# MMCHS1 register map
Vendor: Texas Instruments
Registers are 32-bit, access per field, reset 0x0 unless marked. A register's access mark holds for its fields unless they carry their own. Offsets are as the file gives them; [hi:lo] are bit positions.

## MMCHS1 (part 2 of 2)
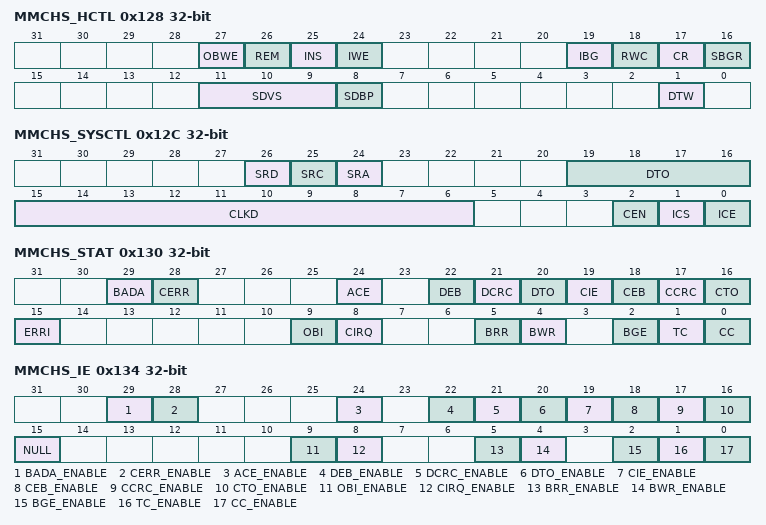
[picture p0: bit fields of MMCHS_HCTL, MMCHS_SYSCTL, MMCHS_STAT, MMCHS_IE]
0x128 MMCHS_HCTL — Control register. This register defines the host controls to set power, wake up and transfer parameters. MMCi.[31:24] = Wake-up control MMCi.[23:16] = Block gap control MMCi.[15:8] = Power control MMCi.[7:0] = Host control
  [27] OBWE rw — Wake-up event enable for 'Out-of-Band' Interrupt.This bit enables wake-up events for 'Out-of-Band' assertion. Wakeup is generated if the wake-up feature is enabled (MMCi.MMCHS_SYSCONFIG[2] ENAWAKEUP bit). The write to this register is ignored when MMCi.MMCHS_CON[14] OBIE bit is not set.
    0=Disable wakeup on 'Out-of-Band' Interrupt; 1=Enable wakeup on 'Out-of-Band' Interrupt
  [26] REM rw — Wake-up event enable on SD card removal.This bit enables wake-up events for card removal assertion. Wakeup is generated if the wake-up feature is enabled (MMCi.MMCHS_SYSCONFIG[2] ENAWAKEUP bit).
    0=Disable wakeup on card removal; 1=Enable wakeup on card removal
  [25] INS rw — Wake-up event enable on SD card insertionThis bit enables wake-up events for card insertion assertion. Wakeup is generated if the wake-up feature is enabled (MMCi.MMCHS_SYSCONFIG[2] ENAWAKEUP bit).
    0=Disable wakeup on card insertion; 1=Enable wakeup on card insertion
  [24] IWE rw — Wake-up event enable on SD card interrupt.This bit enables wake-up events for card interrupt assertion. Wakeup is generated if the wake-up feature is enabled (MMCi.MMCHS_SYSCONFIG[2] ENAWAKEUP bit) and enable status bit is set (MMCi.MMCHS_IE[8] CIRQ_ENABLE bit).
    0=Disable wakeup on card interrupt; 1=Enable wakeup on card interrupt
  [19] IBG rw — Interrupt block at gap.This bit is valid only in 4-bit mode of SDIO card to enable interrupt detection in the interrupt cycle at block gap for a multiple block transfer. For MMC cards and for SD card this bit should be set to 0.
    0=Disable interrupt detection at the block gap in 4-bit mode; 1=Enable interrupt detection at the block gap in 4-bit mode
  [18] RWC rw — Read wait control.The read wait function is optional only for SDIO cards. If the card supports read wait, this bit must be enabled, then requesting a stop at block gap (MMCi.MMCHS_HCTL[16] SBGR bit) generates a read wait period after the current end of block. Be careful, if read wait is not supported it may cause a conflict on mmci_dat line.
    0=Disable Read Wait Control. Suspend/Resume cannot be supported.; 1=Enable Read Wait Control
  [17] CR rw — Continue request.This bit is used to restart a transaction that was stopped by requesting a stop at block gap (MMCi.MMCHS_HCTL[16] SBGR bit). Set this bit to 1 restarts the transfer. The bit is automatically set to 0 by the host controller when transfer has restarted i.e. mmci_dat line is active (MMCi.MMCHS_PSTATE[2] DLA bit) or transferring data (MMCi.MMCHS_PSTATE[8] WTA bit).The Stop at block gap request must be disabled (MMCi.MMCHS_HCTL[16] SBGR bit =0) before setting this bit.
    0=No affect; 1=transfer restart
  [16] SBGR rw — Stop at block gap request. This bit is used to stop executing a transaction at the next block gap. The transfer can restart with a continue request (MMCi.MMCHS_HCTL[17] CR bit) or during a suspend/resume sequence. In case of read transfer, the card must support read wait control. In case of write transfer, the host driver shall set this bit after all block data written. Until the transfer completion (MMCi.MMCHS_STAT[1] TC bit set to 1), the host driver shall leave this bit set to 1.If this bit is set, the local host shall not write to the data register (MMCi.MMCHS_DATA).
    0=Transfer mode; 1=Stop at block gap
  [11:9] SDVS rw — SD bus voltage select (All cards).The host driver should set these bits to select the voltage level for the card according to the voltage supported by the system (MMCi.MMCHS_CAPA[26] VS18 bit, MMCi.MMCHS_CAPA[25] VS30 bit, MMCi.MMCHS_CAPA[24] VS33 bit) before starting a transfer.MMCHS2: This field must be set to 0x5. . MMCHS3: This field must be set to 0x5. .
    5=1.8V (Typical); 6=3.0V (Typical); 7=3.3V (Typical)
  [8] SDBP rw — SD bus power.Before setting this bit, the host driver shall select the SD bus voltage (MMCi.MMCHS_HCTL[11:9] SDVS bits). If the host controller detects the No card state, this bit is automatically set to 0. If the module is power off, a write in the command register (MMCi.MMCHS_CMD) will not start the transfer. A write to this bit has no effect if the selected SD bus voltage is not supported according to capability register (MMCi.MMCHS_CAPA[VS*]).
    0=Power off; 1=Power on
  [1] DTW rw — Data transfer width.For MMC card, this bit must be set following a valid SWITCH command (CMD6) with the correct value and extend CSD index written in the argument. Prior to this command, the MMC card configuration register (CSD and EXT_CSD) must be verified for compliance with This register has no effect when the MMC 8-bit mode is selected (MMCi.MMCHS_CON[5] DW8 bit set to 1)For SD/SDIO cards, this bit must be set following a valid SET_BUS_WIDTH command (ACMD6) with the value written in bit 1 of the argument. Prior to this command, the SD card configuration register (SCR) must be verified for the supported bus width by the SD card.
    0=1-bit Data width (mmci_dat[0] used); 1=4-bit Data width (mmci_dat[3:0] used)
0x12C MMCHS_SYSCTL — SD system control register. This register defines the system controls to set software resets, clock frequency management and data timeout. [31:24] = Software resets [23:16] = Timeout control [15:0] = Clock control
  [26] SRD rw — Software reset for mmci_dat line. This bit is set to 1 for reset and released to 0 when completed .mmci_dat finite state machine in both clock domain are also reset. Here below are the registers cleared by the MMCHS_SYSCTL[26] SRD bit: MMCi.MMCHS_DATA MMCi.MMCHS_PSTATE: BRE, BWE, RTA, WTA, DLA and DATI MMCi.MMCHS_HCTL: SBGR and CR MMCi.MMCHS_STAT: BRR, BWR, BGE and TC Interconnect and MMC buffer data management is reinitialized.
    0=Reset completed; 1=Software reset for mmci_dat line
  [25] SRC rw — Software reset for mmci_cmd line. This bit is set to 1 for reset and released to 0 when completed. mmci_cmd finite state machine in both clock domain are also reset. Here below the registers cleared by the MMCi.MMCHS_SYSCTL[25] SRC bit: MMCi.MMCHS_PSTATE: CMDI MMCi.MMCHS_STAT: CC Interconnect and MMC command status management is reinitialized.
    0=Reset completed; 1=Software reset for mmci_cmd line
  [24] SRA rw — Software reset for all. This bit is set to 1 for reset , and released to 0 when completed. This reset affects the entire host controller except for the card detection circuit and capabilities registers.
    0=Reset completed; 1=Software reset for all the design
  [19:16] DTO rw — Data timeout counter value and busy timeout. This value determines the interval by which mmci_dat lines timeouts are detected.The host driver needs to set this bit field based on - the maximum read access time (NAC) (Refer to the SD Specification Part1 Physical Layer), - the data read access time values (TAAC and NSAC) in the card specific data register (CSD) of the card, - the timeout clock base frequency (MMCi.MMCHS_CAPA[5:0] TCF bits). If the card does not respond within the specified number of cycles, a data timeout error occurs (MMCi.MMCHS_STAT[20] DTO bit). The MMCi.MMCHS_SYSCTL[19,16] DTO bit field is also used to check busy duration, to generate busy timeout for commands with busy response or for busy programming during a write command. Timeout on CRC status is generated if no CRC token is present after a block write.
    0=TCF x 2^13; 1=TCF x 2^14; 14=TCF x 2^27
  [15:6] CLKD rw — Clock frequency select These bits define the ratio between a reference clock frequency (system dependant) and the output clock frequency on the mmci_clk pin of either the memory card (MMC, SD or SDIO).
    0=Clock Ref bypass; 1=Clock Ref bypass; 2=Clock Ref / 2; 3=Clock Ref / 3; 0x3FF=Clock Ref / 1023
  [2] CEN rw — Clock enable. This bit controls if the clock is provided to the card or not.
    0=The clock is not provided to the card . Clock frequency can be changed .; 1=The clock is provided to the card and can be automatically gated when MMCi.[0] AUTOIDLE bit is set to 1 (default value) .The host driver shall wait to set this bit to 1 until the Internal clock is stable (MMCi.[1] ICS bit)
  [1] ICS ro — Internal clock stable (status)This bit indicates either the internal clock is stable or not.
    0=ICS_0_r (The internal clock is not stable.); 1=ICS_1_r (The internal clock is stable after enabling the clock (MMCi.[0] ICE bit) or after changing the clock ratio (MMCi.[15:6] CLKD bits).)
  [0] ICE rw — Internal clock enable. This register controls the internal clock activity.In very low power state, the internal clock is stopped. Note: The activity of the debounce clock (used for wake-up events) and the interface clock (used for reads and writes to the module register map) are not affected by this register.
    0=The internal clock is stopped (very low power state); 1=The internal clock oscillates and can be automatically gated when MMCi.[0] AUTOIDLE bit is set to 1 (default value) 
0x130 MMCHS_STAT — Interrupt status register The interrupt status regroups all the status of the module internal events that can generate an interrupt. [31:16] = Error Interrupt Status [15:0] = Normal Interrupt Status
  [29] BADA rw — Bad access to data space.This bit is set automatically to indicate a bad access to buffer when not allowed:- During a read access to the data register (MMCi.MMCHS_DATA) while buffer reads are not allowed (MMCi.MMCHS_PSTATE[11] BRE bit =0)- During a write access to the data register (MMCi.MMCHS_DATA) while buffer writes are not allowed (MMCi.MMCHS_PSTATE[10] BWE bit=0)
    0=BADA_0_r (No Interrupt.); 0=BADA_0_w (Status bit unchanged); 1=BADA_1_r (Bad Access); 1=BADA_1_w (Status is cleared)
  [28] CERR rw — Card error.This bit is set automatically when there is at least one error in a response of type R1, R1b, R6, R5 or R5b. Only bits referenced as type E (error) in status field in the response can set a card status error. An error bit in the response is flagged only if corresponding bit in card status response error MMCi.MMCHS_CSRE in set.There is no card error detection for autoCMD12 command. The host driver shall read MMCi.MMCHS_RSP76 register to detect error bits in the command response.
    0=CERR_0_r (No Error); 0=CERR_0_w (Status bit unchanged); 1=CERR_1_r (Card error); 1=CERR_1_w (Status is cleared)
  [24] ACE rw — Auto CMD12 error.This bit is set automatically when one of the bits in Auto CMD12 Error status register has changed from 0 to 1.
    0=ACE_0_r (No Error); 0=ACE_0_w (Status bit unchanged); 1=ACE_1_r (AutoCMD12 error); 1=ACE_1_w (Status is cleared)
  [22] DEB rw — Data End Bit error.This bit is set automatically when detecting a 0 at the end bit position of read data on mmci_dat line or at the end position of the CRC status in write mode.
    0=DEB_0_r (No Error); 0=DEB_0_w (Status bit unchanged); 1=DEB_1_r (Data end bit error); 1=DEB_1_w (Status is cleared)
  [21] DCRC rw — Data CRC Error.This bit is set automatically when there is a CRC16 error in the data phase response following a block read command or if there is a 3-bit CRC status different of a position '010' token during a block write command.
    0=DCRC_0_r (No Error.); 0=DCRC_0_w (Status bit unchanged); 1=DCRC_1_r (Data CRC error); 1=DCRC_1_w (Status is cleared)
  [20] DTO rw — Data timeout error. This bit is set automatically according to the following conditions:- Busy timeout for R1b, R5b response type. - Busy timeout after write CRC status.- Write CRC status timeout.- Read data timeout.
    0=DTO_0_r (No error); 0=DTO_0_w (Status bit unchanged); 1=DTO_1_r (Time out); 1=DTO_1_w (Status is cleared)
  [19] CIE rw — Command index error.This bit is set automatically when response index differs from corresponding command index previously emitted. It depends on the enable bit (MMCi.MMCHS_CMD[20] CICE).
    0=CIE_0_r (No error); 0=CIE_0_w (Status bit unchanged); 1=CIE_1_r (Command index error); 1=CIE_1_w (Status is cleared)
  [18] CEB rw — Command end bit error.This bit is set automatically when detecting a 0 at the end bit position of a command response.
    0=CEB_0_r (No error); 0=CEB_0_w (Status bit unchanged); 1=CEB_1_r (Command end bit error); 1=CEB_1_w (Status is cleared)
  [17] CCRC rw — Command CRC Error.This bit is set automatically when there is a CRC7 error in the command response depending on the enable bit (MMCi.MMCHS_CMD[19] CCCE).
    0=CCRC_0_r (No Error); 0=CCRC_0_w (Status bit unchanged); 1=CCRC_1_r (Command CRC error); 1=CCRC_1_w (Status is cleared)
  [16] CTO rw — Command Timeout Error. This bit is set automatically when no response is received within 64 clock cycles from the end bit of the command.For commands that reply within 5 clock cycles - the timeout is still detected at 64 clock cycles.
    0=CTO_0_r (No error); 0=CTO_0_w (Status bit unchanged); 1=CTO_1_r (Time Out); 1=CTO_1_w (Status is cleared)
  [15] ERRI ro — Error Interrupt.If any of the bits in the Error Interrupt Status register (MMCi.MMCHS_STAT[31:16]) are set, then this bit is set to 1. Therefore the host driver can efficiently test for an error by checking this bit first.Writes to this bit are ignored.
    0=ERRI_0_r (No Interrupt); 1=ERRI_1_r (Error interrupt event(s) occurred)
  [9] OBI ro — Out-Of-Band interrupt (This interrupt is only useful for MMC card).This bit is set automatically when MMCi.MMCHS_CON[14] OBIE bit is set and an Out-of-Band interrupt occurs on OBI pin.The interrupt detection depends on polarity controlled by MMCi.MMCHS_CON[13] OBIP bit.The Out-of-Band interrupt signal is a system specific feature for future use, this signal is not required for existing specification implementation.
    0=OBI_0_r (No Out-Of-Band interrupt.); 0=OBI_0_w (Status bit unchanged.); 1=OBI_1_r (Interrupt Out-Of-Band occurs.); 1=OBI_1_w (Status is cleared.)
  [8] CIRQ ro — Card interrupt.This bit is only used for SD and SDIO cards.In 1-bit mode, interrupt source is asynchronous (can be a source of asynchronous wakeup).In 4-bit mode, interrupt source is sampled during the interrupt cycle.In CE-ATA mode, interrupt source is detected when the card drives mmci_cmd line to zero during one cycle after data transmission end.All modes above are fully exclusive.The controller interrupt must be clear by setting MMCi.MMCHS_IE[8] CIRQ_ENABLE to 0, then the host driver must start the interrupt service with card (clearing card interrupt status) to remove card interrupt source. Otherwise the Controller interrupt will be reasserted as soon as MMCi.MMCHS_IE[8] CIRQ_ENABLE is set to 1.Writes to this bit are ignored.
    0=CIRQ_0_r (No card interrupt); 1=CIRQ_1_r (Generate card interrupt)
  [5] BRR rw — Buffer read ready.This bit is set automatically during a read operation to the card (see class 2 - block oriented read commands) when one block specified by the MMCi.MMCHS_BLK[10:0] BLEN bit field is completely written in the buffer. It indicates that the memory card has filled out the buffer and that the local host needs to empty the buffer by reading it.Note: If the DMA receive-mode is enabled, this bit is never set; instead a DMA receive request to the main DMA controller of the system is generated.
    0=BRR_0_r (Not Ready to read buffer); 0=BRR_0_w (Status bit unchanged); 1=BRR_1_r (Ready to read buffer); 1=BRR_1_w (Status is cleared)
  [4] BWR rw — Buffer write ready.This bit is set automatically during a write operation to the card (see class 4 - block oriented write command) when the host can write a complete block as specified by MMCi.MMCHS_BLK[10:0] BLEN. It indicates that the memory card has emptied one block from the buffer and that the local host is able to write one block of data into the buffer.Note: If the DMA transmit mode is enabled, this bit is never set; instead, a DMA transmit request to the main DMA controller of the system is generated.
    0=BWR_0_r (Not Ready to write buffer); 0=BWR_0_w (Status bit unchanged); 1=BWR_1_r (Ready to write buffer); 1=BWR_1_w (Status is cleared)
  [2] BGE rw — Block gap event.When a stop at block gap is requested (MMCi.MMCHS_HCTL[16] SBGR bit), this bit is automatically set when transaction is stopped at the block gap during a read or write operation.This event does not occur when the stop at block gap is requested on the last block.In read mode, a 1-to-0 transition of the mmci_dat line active status (MMCi.MMCHS_PSTATE[2] DLA bit) between data blocks generates a Block gap event interrupt.
    0=BGE_0_r (No block gap event); 0=BGE_0_w (Status bit unchanged); 1=BGE_1_r (Transaction stopped at block gap); 1=BGE_1_w (Status is cleared)
  [1] TC rw — Transfer completed.This bit is always set when a read/write transfer is completed or between two blocks when the transfer is stopped due to a stop at block gap request (MMCi.MMCHS_HCTL[16] SBGR bit).This bit is also set when exiting a command in a busy state (if the command has a busy notification capability).In Read mode: This bit is automatically set on completion of a read transfer (MMCi.MMCHS_PSTATE[9] RTA bit).In write mode: This bit is set automatically on completion of the mmci_dat line use (MMCi.MMCHS_PSTATE[2] DLA bit).
    0=TC_0_r (No transfer complete); 0=TC_0_w (Status bit unchanged); 1=TC_1_r (Data transfer complete); 1=TC_1_w (Status is cleared)
  [0] CC rw — Command complete.This bit is set when a 1-to-0 transition occurs in the register command inhibit (MMCi.MMCHS_PSTATE[0] CMDI bit)If the command is a type for which no response is expected, then the command complete interrupt is generated at the end of the command. A command timeout error (MMCi.MMCHS_STAT[16] CTO bit) has higher priority than command complete (MMCi.MMCHS_STAT[0] CC bit).If a response is expected but none is received, then a command timeout error is detected and signaled instead of the command complete interrupt.
    0=CC_0_r (No Command complete); 0=CC_0_w (Status bit unchanged); 1=CC_1_r (Command complete); 1=CC_1_w (Status is cleared)
0x134 MMCHS_IE — Interrupt SD enable registerThis register allows to enable/disable the module to set status bits, on an event-by-event basis. [31:16] = Error Interrupt Status Enable [15:0] = Normal Interrupt Status Enable
  [29] BADA_ENABLE rw — Bad access to data space Interrupt Enable
    0=Masked; 1=Enabled
  [28] CERR_ENABLE rw — Card error interrupt Enable
    0=Masked; 1=Enabled
  [24] ACE_ENABLE rw — Auto CMD12 error Interrupt Enable
    0=Masked; 1=Enabled
  [22] DEB_ENABLE rw — Data end bit error Interrupt Enable
    0=Masked; 1=Enabled
  [21] DCRC_ENABLE rw — Data CRC error Interrupt Enable
    0=Masked; 1=Enabled
  [20] DTO_ENABLE rw — Data timeout error Interrupt Enable
    0=The data timeout detection is deactivated.The host controller provides the clock to the card until the card sends the data or the transfer is aborted; 1=The data timeout detection is enabled
  [19] CIE_ENABLE rw — Command index error Interrupt Enable
    0=Masked; 1=Enabled
  [18] CEB_ENABLE rw — Command end bit error Interrupt Enable
    0=Masked; 1=Enabled
  [17] CCRC_ENABLE rw — Command CRC error Interrupt Enable
    0=Masked; 1=Enabled
  [16] CTO_ENABLE rw — Command timeout error Interrupt Enable
    0=Masked; 1=Enabled
  [15] NULL ro — Fixed to 0 The host driver shall control error interrupts using the Error Interrupt Signal Enable register. Writes to this bit are ignored.
  [9] OBI_ENABLE rw — Out-of-Band interrupt Enable A write to this register when MMCi.MMCHS_CON[14] OBIE is set to '0' is ignored.
    0=Masked; 1=Enabled
  [8] CIRQ_ENABLE rw — Card interrupt Enable A clear of this bit also clears the corresponding status bit.During 1-bit mode, if the interrupt routine does not remove the source of a card interrupt in the SDIO card, the status bit is reasserted when this bit is set to 1.This bit must be set to 1 when entering in smart idle mode to enable system to identity wakeup event and to allow controller to clear internal wakeup source.
    0=Masked; 1=Enabled
  [5] BRR_ENABLE rw — Buffer Read Ready Interrupt Enable
    0=Masked; 1=Enabled
  [4] BWR_ENABLE rw — Buffer Write Ready Interrupt Enable
    0=Masked; 1=Enabled
  [2] BGE_ENABLE rw — Block Gap Event Interrupt Enable
    0=Masked; 1=Enabled
  [1] TC_ENABLE rw — Transfer completed Interrupt Enable
    0=Masked; 1=Enabled
  [0] CC_ENABLE rw — Command completed Interrupt Enable
    0=Masked; 1=Enabled
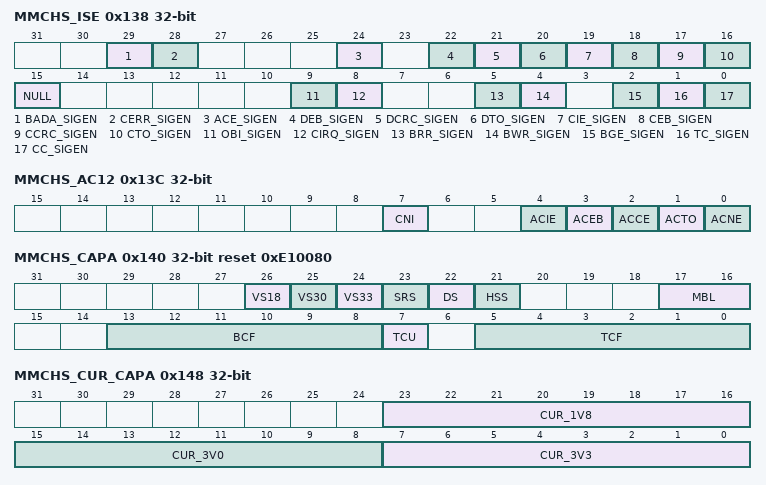
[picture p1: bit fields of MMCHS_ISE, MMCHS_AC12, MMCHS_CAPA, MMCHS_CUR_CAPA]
0x138 MMCHS_ISE — Interrupt signal enable registerThis register allows to enable/disable the module internal sources of status, on an event-by-event basis. [31:16] = Error Interrupt Signal Enable [15:0] = Normal Interrupt Signal Enable
  [29] BADA_SIGEN rw — Bad access to data space signal status Enable
    0=Masked; 1=Enabled
  [28] CERR_SIGEN rw — Card error interrupt signal status Enable
    0=Masked; 1=Enabled
  [24] ACE_SIGEN rw — Auto CMD12 error signal status Enable
    0=Masked; 1=Enabled
  [22] DEB_SIGEN rw — Data end bit error signal status Enable
    0=Masked; 1=Enabled
  [21] DCRC_SIGEN rw — Data CRC error signal status Enable
    0=Masked; 1=Enabled
  [20] DTO_SIGEN rw — Data timeout error signal status Enable
    0=Masked; 1=Enabled
  [19] CIE_SIGEN rw — Command index error signal status Enable
    0=Masked; 1=Enabled
  [18] CEB_SIGEN rw — Command end bit error signal status Enable
    0=Masked; 1=Enabled
  [17] CCRC_SIGEN rw — Command CRC error signal status Enable
    0=Masked; 1=Enabled
  [16] CTO_SIGEN rw — Command timeout error signal status Enable
    0=Masked; 1=Enabled
  [15] NULL ro — Fixed to 0 The host driver shall control error interrupts using the Error Interrupt Signal Enable register. Writes to this bit are ignored
  [9] OBI_SIGEN rw — Out-Of-Band Interrupt signal status Enable.A write to this register when MMCHS_CON[14] OBIE bit is set to '0' is ignored.
    0=Masked; 1=Enabled
  [8] CIRQ_SIGEN rw — Card interrupt signal status Enable
    0=Masked; 1=Enabled
  [5] BRR_SIGEN rw — Buffer Read Ready signal status Enable
    0=Masked; 1=Enabled
  [4] BWR_SIGEN rw — Buffer Write Ready signal status Enable
    0=Masked; 1=Enabled
  [2] BGE_SIGEN rw — Black Gap Event signal status Enable
    0=Masked; 1=Enabled
  [1] TC_SIGEN rw — Transfer completed signal status Enable
    0=Masked; 1=Enabled
  [0] CC_SIGEN rw — Command completed signal status Enable
    0=Masked; 1=Enabled
0x13C MMCHS_AC12 ro — Auto CMD12 Error Status Register. The host driver may determine which of the errors cases related to Auto CMD12 has occurred by checking this MMCi. register when an Auto CMD12 Error interrupt occurs.This register is valid only when Auto CMD12 is enabled (MMCi.[2] ACEN bit) and Auto CMD12Error (MMCi.[24] ACE bit) is set to 1.Note: These bits are automatically reset when starting a new adtc command with data.
  [7] CNI — Command not issue by Auto CMD12 error. If this bit is set to 1, it means that pending command is not executed due to Auto CMD12 error: ACEB, ACCE, ACTO or ACNE.
    0=CNI_0_r (Not error); 1=CNI_1_r (Command not issued)
  [4] ACIE — Auto CMD12 index error. This bit is a set to 1 when response index differs from corresponding command auto CMD12 index previously emitted.This bit depends on the command index check enable (MMCi.MMCHS_CMD[20] CICE bit).
    0=ACIE_0_r (No error); 1=ACIE_1_r (Auto CMD12 Index Error)
  [3] ACEB — Auto CMD12 end bit error. This bit is set to 1 when detecting a 0 at the end bit position of auto CMD12 command response.
    0=ACEB_0_r (No error); 1=ACEB_1_r (AutoCMD12 End bit Error)
  [2] ACCE — Auto CMD12 CRC error. This bit is automatically set to 1 when a CRC7 error is detected in the auto CMD12 command response depending on the enable in the MMCi.MMCHS_CMD[19] CCCE bit.
    0=ACCE_0_r (No error); 1=ACCE_1_r (Auto CMD12 CRC Error)
  [1] ACTO — Auto CMD12 timeout error. This bit is set to 1 if no response is received within 64 clock cycles from the end bit of the auto CMD12 command.
    0=ACTO_0_r (No error); 1=ACTO_1_r (Auto CMD12 Time Out)
  [0] ACNE — Auto CMD12 not executed. This bit is set to 1 if multiple block data transfer command has started and if an error occurs in command before Auto CMD12 starts.
    0=ACNE_0_r (Auto CMD12 Executed); 1=ACNE_1_r (Auto CMD12 Not Executed)
0x140 MMCHS_CAPA reset 0xE10080 — Capabilities register. This register lists the capabilities of the MMC/SD/SDIO host controller.
  [26] VS18 rw — Voltage support 1.8V Initialization of this register (via a write access to this register) depends on the system capabilities. The host driver shall not modify this register after the initialization. This register is only reinitialized by a hard reset (via MMCi_RESET signal).MMCHS1, 2 and 3: This bit must be set to 1. .
    0=VS18_0_r (1.8 V Not Supported); 0=VS18_0_w (1.8 V Not supported); 1=VS18_1_r (1.8 V Supported); 1=VS18_1_w (1.8 V Supported)
  [25] VS30 rw — Voltage support 3.0V Initialization of this register (via a write access to this register) depends on the system capabilities. The host driver shall not modify this register after the initialization. This register is only reinitialized by a hard reset (via MMCi_RESET signal)MMCHS1: This bit must be set to 1. . MMCHS2 and 3: This bit must be left to 0. .
    0=VS30_0_r (3.0 V Not Supported); 0=VS30_0_w (3.0 V Not supported); 1=VS30_1_r (3.0 V Supported); 1=VS30_1_w (3.0 V Supported)
  [24] VS33 rw — Voltage support 3.3V Initialization of this register (via a write access to this register) depends on the system capabilities. The host driver shall not modify this register after the initialization. This register is only reinitialized by a hard reset (via MMCi_RESET signal)MMCHS1, 2 and 3: This bit must be left to 0. .
    0=VS33_0_r (3.3 V Not Supported); 0=VS33_0_w (3.3 V Not supported); 1=VS33_1_r (3.3 V Supported); 1=VS33_1_w (3.3 V Supported)
  [23] SRS ro — Suspend/Resume support (SDIO cards only)This bit indicates whether the host controller supports Suspend/Resume functionality.
    0=SRS_0_r (The Host controller does not Suspend/Resume functionality.); 1=SRS_1_r (The Host controller supports Suspend/Resume functionality.)
  [22] DS ro — DMA support. This bit indicates that the Host Controller is able to use DMA to transfer data between system memory and the Host Controller directly.
    0=DS_0_r (DMA Not Supported); 1=DS_1_r (DMA Supported)
  [21] HSS ro — High speed support. This bit indicates that the host controller supports high speed operations and can supply an up-to-52 MHz clock to the card.
    0=HSS_0_r (High Speed Not Supported); 1=HSS_1_r (High Speed Supported)
  [17:16] MBL ro — Maximum block length. This value indicates the maximum block size that the host driver can read and write to the buffer in the host controller.The host controller supports 512 bytes and 1024 bytes block transfers.
    0=MBL_0_r (512 bytes); 1=MBL_1_r (1024 bytes); 2=MBL_2_r (2048 bytes)
  [13:8] BCF ro — Base clock frequency for clock provided to the card.
    0=BCF_0_r (The value indicating the base (maximum) frequency for the output clock provided to the card is system dependent and is not available in this register. Get the information via another method. See, Power Reset and Clock Management, for more information on the value of FUNC_96M_CLK clock signal.)
  [7] TCU ro — Timeout clock unit. This bit shows the unit of base clock frequency used to detect Data Timeout Error (MMCi.MMCHS_STAT[20] DTO bit).
    0=TCU_0_r (kHz); 1=TCU_1_r (MHz)
  [5:0] TCF ro — Timeout clock frequency. The timeout clock frequency is used to detect Data Timeout Error (MMCi.MMCHS_STAT[20] DTO bit).
    0=TCF_0_r (The timeout clock frequency depends on the frequency of the clock provided to the card. The value of the timeout clock frequency is not available in this register. Note:You can have the timeout clock frequency by dividing FUNC_96M_CLK by the value of the MMCi.[15:6] CLKD bit field.)
0x148 MMCHS_CUR_CAPA — Maximum current capabilities Register. This register indicates the maximum current capability for each voltage. The value is meaningful if the voltage support is set in the capabilities register (MMCi.). Initialization of this register (via a write access to this register) depends on the system capabilities. The host driver shall not modify this register after the initialization. This register is only reinitialized by a hard reset (via MMCi_RESET signal)
  [23:16] CUR_1V8 rw — Maximum current for 1.8 V
  [15:8] CUR_3V0 rw — Maximum current for 3.0 V
  [7:0] CUR_3V3 rw — Maximum current for 3.3 V
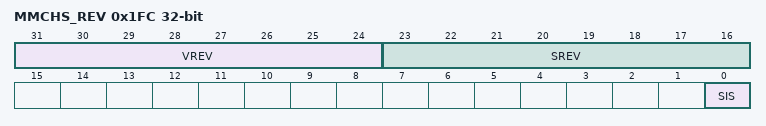
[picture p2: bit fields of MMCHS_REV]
0x1FC MMCHS_REV ro (reset mask 0xFFFFFF) — Versions Register. This register contains the hard coded RTL vendor revision number, the version number of SD specification compliancy and a slot status bit.MMCi.[31:16] = Host controller versionMMCi.[15:0] = Slot Interrupt Status
  [31:24] VREV — Vendor Version Number: IP revision[31:28] Major revision[27:24] Minor revision Examples: 0x10 for 1.0 0x21 for 2.1
  [23:16] SREV — Specification Version Number. This status indicates the Standard SD Host Controller Specification Version. The upper and lower 4-bits indicate the version.
    0=SREV_0_r (SD Host Specification Version 1.0)
  [0] SIS — Slot Interrupt Status. This status bit indicates the inverted state of interrupt signal for the module.By a power on reset or by setting a software reset for all (MMCi.MMCHS_SYSCTL[24] SRA), the interrupt signal shall be deasserted and this status shall read 0.
